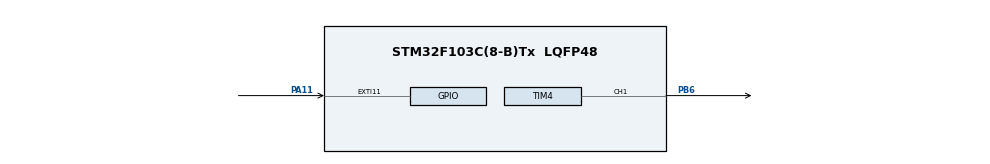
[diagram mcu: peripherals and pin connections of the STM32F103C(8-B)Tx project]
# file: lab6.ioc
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Mcu.Family=STM32F1
Mcu.Name=STM32F103C(8-B)Tx
Mcu.Package=LQFP48
NVIC.EXTI15_10_IRQn=true\:0\:0\:false\:false\:true\:true\:true\:true
NVIC.PriorityGroup=NVIC_PRIORITYGROUP_4
PA11.Signal=GPXTI11
PA13.Mode=Serial_Wire
PA13.Signal=SYS_JTMS-SWDIO
PA14.Mode=Serial_Wire
PA14.Signal=SYS_JTCK-SWCLK
PB6.Signal=S_TIM4_CH1
PC14-OSC32_IN.Mode=LSE-External-Clock-Source
PC14-OSC32_IN.Signal=RCC_OSC32_IN
PC15-OSC32_OUT.Mode=LSE-External-Clock-Source
PC15-OSC32_OUT.Signal=RCC_OSC32_OUT
PD0-OSC_IN.Mode=HSE-External-Clock-Source
PD0-OSC_IN.Signal=RCC_OSC_IN
PD1-OSC_OUT.Mode=HSE-External-Clock-Source
PD1-OSC_OUT.Signal=RCC_OSC_OUT
ProjectManager.HeapSize=0x200
ProjectManager.StackSize=0x400
ProjectManager.TargetToolchain=STM32CubeIDE
RCC.APB1Freq_Value=8000000
RCC.APB2Freq_Value=8000000
SH.S_TIM4_CH1.0=TIM4_CH1,PWM Generation1 CH1
TIM4.Channel-PWM\ Generation1\ CH1=TIM_CHANNEL_1
TIM4.Period=999
TIM4.Prescaler=3
TIM4.Pulse-PWM\ Generation1\ CH1=799
board=custom

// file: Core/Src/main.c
/* USER CODE BEGIN Header */
/**
  ******************************************************************************
  * @file           : main.c
  * @brief          : Main program body
  ******************************************************************************
  * @attention
  *
  * Copyright (c) 2026 STMicroelectronics.
  * All rights reserved.
  *
  * This software is licensed under terms that can be found in the LICENSE file
  * in the root directory of this software component.
  * If no LICENSE file comes with this software, it is provided AS-IS.
  *
  ******************************************************************************
  *variant 3 generate pwm freq = 2kHz, Button - cyclic change duty cycle: 10%-25%-50%-75%-99%
  *
  *CONNECTIONS
  *PB6 - PWM out
  *PA11 - button
  *
  */
/* USER CODE END Header */
#include "main.h"

TIM_HandleTypeDef htim4;

void SystemClock_Config(void);
static void MX_GPIO_Init(void);
static void MX_TIM4_Init(void);

/* USER CODE BEGIN 0 */
uint8_t pwmMode = 0;
volatile uint32_t lastISR = 0;

void HAL_GPIO_EXTI_Callback(uint16_t GPIO_Pin)
{
	//program debounce
	if(HAL_GetTick() - lastISR >= 200)
	{
		lastISR = HAL_GetTick();
		if(GPIO_Pin == GPIO_PIN_11)
		{
			pwmMode = (pwmMode+1)%5;
		}
	}
}
/* USER CODE END 0 */

int main(void)
{

  /* MCU Configuration--------------------------------------------------------*/

  /* Reset of all peripherals, Initializes the Flash interface and the Systick. */
  HAL_Init();

  /* Configure the system clock */
  SystemClock_Config();

  /* Initialize all configured peripherals */
  MX_GPIO_Init();
  MX_TIM4_Init();
  /* USER CODE BEGIN 2 */
  HAL_TIM_PWM_Start(&htim4, TIM_CHANNEL_1);
  uint16_t dutyCycle = 0;

  /* USER CODE END 2 */

  /* Infinite loop */
  /* USER CODE BEGIN WHILE */
  while (1)
  {
	  switch (pwmMode)
	  {
		case 0:
			dutyCycle = 100;
			break;
		case 1:
			dutyCycle = 250;
			break;
		case 2:
			dutyCycle = 500;
			break;
		case 3:
			dutyCycle = 750;
			break;
		case 4:
			dutyCycle = 999;
			break;
		default:
			break;
	  }

	  __HAL_TIM_SET_COMPARE(&htim4, TIM_CHANNEL_1, dutyCycle);
	  HAL_Delay(10);
    /* USER CODE END WHILE */

  }
}

void SystemClock_Config(void)
{
  RCC_OscInitTypeDef RCC_OscInitStruct = {0};
  RCC_ClkInitTypeDef RCC_ClkInitStruct = {0};

  /** Initializes the RCC Oscillators according to the specified parameters
  * in the RCC_OscInitTypeDef structure.
  */
  RCC_OscInitStruct.OscillatorType = RCC_OSCILLATORTYPE_HSI;
  RCC_OscInitStruct.HSIState = RCC_HSI_ON;
  RCC_OscInitStruct.HSICalibrationValue = RCC_HSICALIBRATION_DEFAULT;
  RCC_OscInitStruct.PLL.PLLState = RCC_PLL_NONE;
  if (HAL_RCC_OscConfig(&RCC_OscInitStruct) != HAL_OK)
  {
    Error_Handler();
  }

  /** Initializes the CPU, AHB and APB buses clocks
  */
  RCC_ClkInitStruct.ClockType = RCC_CLOCKTYPE_HCLK|RCC_CLOCKTYPE_SYSCLK
                              |RCC_CLOCKTYPE_PCLK1|RCC_CLOCKTYPE_PCLK2;
  RCC_ClkInitStruct.SYSCLKSource = RCC_SYSCLKSOURCE_HSI;
  RCC_ClkInitStruct.AHBCLKDivider = RCC_SYSCLK_DIV1;
  RCC_ClkInitStruct.APB1CLKDivider = RCC_HCLK_DIV1;
  RCC_ClkInitStruct.APB2CLKDivider = RCC_HCLK_DIV1;

  if (HAL_RCC_ClockConfig(&RCC_ClkInitStruct, FLASH_LATENCY_0) != HAL_OK)
  {
    Error_Handler();
  }
}

static void MX_TIM4_Init(void)
{

  TIM_MasterConfigTypeDef sMasterConfig = {0};
  TIM_OC_InitTypeDef sConfigOC = {0};

  htim4.Instance = TIM4;
  htim4.Init.Prescaler = 3;
  htim4.Init.CounterMode = TIM_COUNTERMODE_UP;
  htim4.Init.Period = 999;
  htim4.Init.ClockDivision = TIM_CLOCKDIVISION_DIV1;
  htim4.Init.AutoReloadPreload = TIM_AUTORELOAD_PRELOAD_DISABLE;
  if (HAL_TIM_PWM_Init(&htim4) != HAL_OK)
  {
    Error_Handler();
  }
  sMasterConfig.MasterOutputTrigger = TIM_TRGO_RESET;
  sMasterConfig.MasterSlaveMode = TIM_MASTERSLAVEMODE_DISABLE;
  if (HAL_TIMEx_MasterConfigSynchronization(&htim4, &sMasterConfig) != HAL_OK)
  {
    Error_Handler();
  }
  sConfigOC.OCMode = TIM_OCMODE_PWM1;
  sConfigOC.Pulse = 799;
  sConfigOC.OCPolarity = TIM_OCPOLARITY_HIGH;
  sConfigOC.OCFastMode = TIM_OCFAST_DISABLE;
  if (HAL_TIM_PWM_ConfigChannel(&htim4, &sConfigOC, TIM_CHANNEL_1) != HAL_OK)
  {
    Error_Handler();
  }
  HAL_TIM_MspPostInit(&htim4);

}

static void MX_GPIO_Init(void)
{
  GPIO_InitTypeDef GPIO_InitStruct = {0};

  /* GPIO Ports Clock Enable */
  __HAL_RCC_GPIOC_CLK_ENABLE();
  __HAL_RCC_GPIOD_CLK_ENABLE();
  __HAL_RCC_GPIOA_CLK_ENABLE();
  __HAL_RCC_GPIOB_CLK_ENABLE();

  /*Configure GPIO pin : PA11 */
  GPIO_InitStruct.Pin = GPIO_PIN_11;
  GPIO_InitStruct.Mode = GPIO_MODE_IT_RISING;
  GPIO_InitStruct.Pull = GPIO_NOPULL;
  HAL_GPIO_Init(GPIOA, &GPIO_InitStruct);

  /* EXTI interrupt init*/
  HAL_NVIC_SetPriority(EXTI15_10_IRQn, 0, 0);
  HAL_NVIC_EnableIRQ(EXTI15_10_IRQn);

}

void Error_Handler(void)
{
  __disable_irq();
  while (1)
  {
  }
}
